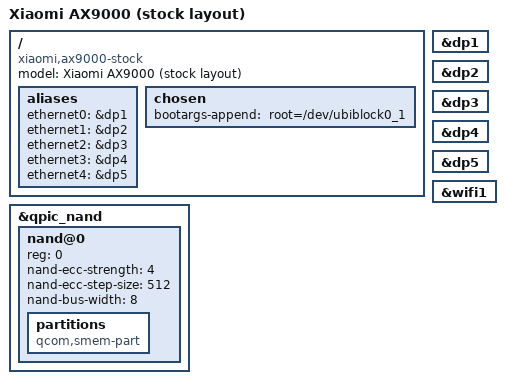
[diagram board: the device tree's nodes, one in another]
// SPDX-License-Identifier: GPL-2.0-or-later OR MIT

#include "ipq8072-ax9000.dts"

/ {
	model = "Xiaomi AX9000 (stock layout)";
	compatible = "xiaomi,ax9000-stock", "qcom,ipq8074";

	aliases {
		/* Aliases as required by u-boot to patch MAC addresses */
		ethernet0 = &dp1;
		ethernet1 = &dp2;
		ethernet2 = &dp3;
		ethernet3 = &dp4;
		ethernet4 = &dp5;
	};

	chosen {
		bootargs-append = " root=/dev/ubiblock0_1";
	};

};

&qpic_nand {
	/delete-node/ partitions;
	/delete-node/ nand@0;

	nand@0 {
		reg = <0>;
		nand-ecc-strength = <4>;
		nand-ecc-step-size = <512>;
		nand-bus-width = <8>;

		partitions {
			compatible = "qcom,smem-part";
		};
	};
};

&dp1 {
	/delete-property/ nvmem-cells;
	/delete-property/ nvmem-cell-names;
};

&dp2 {
	/delete-property/ nvmem-cells;
	/delete-property/ nvmem-cell-names;
};

&dp3 {
	/delete-property/ nvmem-cells;
	/delete-property/ nvmem-cell-names;
};

&dp4 {
	/delete-property/ nvmem-cells;
	/delete-property/ nvmem-cell-names;
};

&dp5 {
	/delete-property/ nvmem-cells;
	/delete-property/ nvmem-cell-names;
};

&wifi1 {
	/delete-property/ nvmem-cells;
	/delete-property/ nvmem-cell-names;
};
